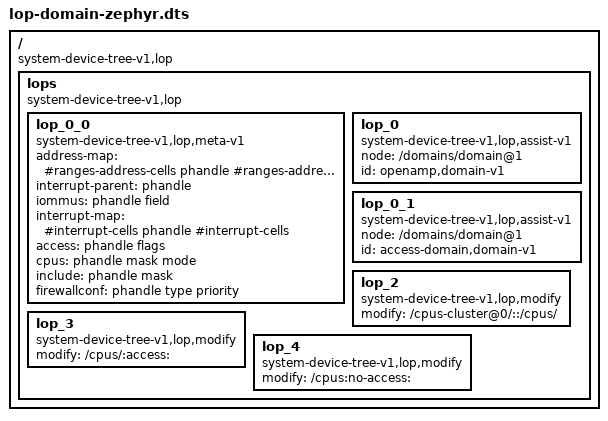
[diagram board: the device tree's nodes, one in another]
/*
 * Copyright (c) 2021 Xilinx Inc. All rights reserved.
 *
 * Author:
 *       Bruce Ashfield <bruce.ashfield@xilinx.com>
 *
 * SPDX-License-Identifier: BSD-3-Clause
 */

/dts-v1/;

/ {
        compatible = "system-device-tree-v1,lop";
        lops {
                compatible = "system-device-tree-v1,lop";
                lop_0_0 {
                        compatible = "system-device-tree-v1,lop,meta-v1","phandle-desc-v1";
                        address-map = "#ranges-address-cells phandle #ranges-address-cells #ranges-size-cells";
                        interrupt-parent = "phandle";
                        iommus = "phandle field";
                        interrupt-map = "#interrupt-cells phandle #interrupt-cells";
                        access = "phandle flags";
                        cpus = "phandle mask mode";
                        include = "phandle mask";
                        firewallconf = "phandle type priority";
                };
                lop_0 {
                        compatible = "system-device-tree-v1,lop,assist-v1";
                        node = "/domains/domain@1";
                        id = "openamp,domain-v1";
                };
                lop_0_1 {
                        compatible = "system-device-tree-v1,lop,assist-v1";
                        node = "/domains/domain@1";
                        id = "access-domain,domain-v1";
                };
                lop_2 {
                        // node name modify
                        compatible = "system-device-tree-v1,lop,modify";
                        modify = "/cpus-cluster@0/::/cpus/";
                };
                lop_3 {
                        compatible = "system-device-tree-v1,lop,modify";
                        // format is: "path":"property":"replacement"
                        //    - modify to "nothing", is a remove operation
                        //    - modify with no property is node operation (rename or remove)
                        modify = "/cpus/:access:";
                };
                lop_4 {
                        // modify to "nothing", is a remove operation
                        compatible = "system-device-tree-v1,lop,modify";
                        modify = "/cpus:no-access:";
                };
        };
};
